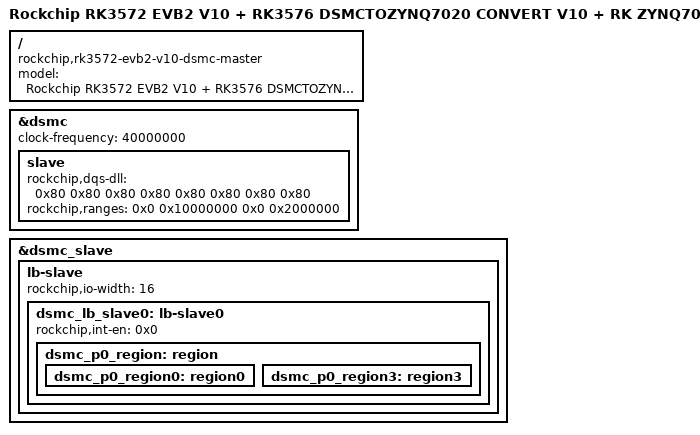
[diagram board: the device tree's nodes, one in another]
// SPDX-License-Identifier: (GPL-2.0+ OR MIT)
/*
 * Copyright (c) 2026 Rockchip Electronics Co., Ltd.
 */

/dts-v1/;

#include "rk3572-evb2-v10.dtsi"
#include "rk3572-linux.dtsi"

/ {
	model = "Rockchip RK3572 EVB2 V10 + RK3576 DSMCTOZYNQ7020 CONVERT V10 + RK ZYNQ7020 V10";
	compatible = "rockchip,rk3572-evb2-v10-dsmc-master", "rockchip,rk3572";
};

&dsmc {
	clock-frequency = <40000000>;
	status = "okay";
	slave {
		rockchip,dqs-dll = <0x80 0x80
				    0x80 0x80
				    0x80 0x80
				    0x80 0x80>;
		rockchip,ranges = <0x0 0x10000000 0x0 0x2000000>;
	};
};

&dsmc_slave {
	status = "okay";
	lb-slave {
		rockchip,io-width = <16>;
		dsmc_lb_slave0: lb-slave0 {
			rockchip,int-en = <0x0>;
			status = "okay";
			dsmc_p0_region: region {
				dsmc_p0_region0: region0 {
					status = "okay";
				};
				dsmc_p0_region3: region3 {
					status = "okay";
				};
			};
		};
	};
};
